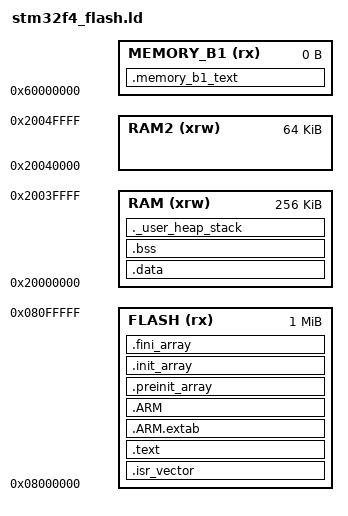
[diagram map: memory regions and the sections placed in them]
/*
*****************************************************************************
**
**  File        : stm32f4_flash.ld
**
**  Abstract    : Linker script for STM32F407VG Device with
**                1024KByte FLASH, 192KByte RAM
**
**                Set heap size, stack size and stack location according
**                to application requirements.
**
**                Set memory bank area and size if external memory is used.
**
**  Target      : STMicroelectronics STM32
**
**  Environment : Atollic TrueSTUDIO(R)
**
**  Distribution: The file is distributed "as is," without any warranty
**                of any kind.
**
**  (c)Copyright Atollic AB.
**  You may use this file as-is or modify it according to the needs of your
**  project. Distribution of this file (unmodified or modified) is not
**  permitted. Atollic AB permit registered Atollic TrueSTUDIO(R) users the
**  rights to distribute the assembled, compiled & linked contents of this
**  file as part of an application binary file, provided that it is built
**  using the Atollic TrueSTUDIO(R) toolchain.
**
*****************************************************************************
*/

/* Entry Point */
ENTRY(Reset_Handler)

/* Highest address of the user mode stack */
enter_bootloader_mode = 0x2001FFFC;
_estack = 0x2001FFFC;    /* end of 128K RAM on AHB bus*/
_app_start = 0x08004000; /* Reserve Sector 0(16K) for bootloader */

/* Generate a link error if heap and stack don't fit into RAM */
_Min_Heap_Size = 0;      /* required amount of heap  */
_Min_Stack_Size = 0x400; /* required amount of stack */

/* Specify the memory areas */
MEMORY
{
  FLASH (rx)      : ORIGIN = 0x08000000, LENGTH = 1024K
  RAM (xrw)       : ORIGIN = 0x20000000, LENGTH = 256K
  RAM2 (xrw)      : ORIGIN = 0x20040000, LENGTH = 64K
  MEMORY_B1 (rx)  : ORIGIN = 0x60000000, LENGTH = 0K
}

/* Define output sections */
SECTIONS
{
  /* The startup code goes first into FLASH */
  .isr_vector :
  {
    . = ALIGN(4);
    KEEP(*(.isr_vector)) /* Startup code */
    . = ALIGN(4);
  } >FLASH

  /* The program code and other data goes into FLASH */
  .text :
  {
    . = ALIGN(4);
    *(.text)           /* .text sections (code) */
    *(.text*)          /* .text* sections (code) */
    *(.rodata)         /* .rodata sections (constants, strings, etc.) */
    *(.rodata*)        /* .rodata* sections (constants, strings, etc.) */
    *(.glue_7)         /* glue arm to thumb code */
    *(.glue_7t)        /* glue thumb to arm code */
	*(.eh_frame)

    KEEP (*(.init))
    KEEP (*(.fini))

    . = ALIGN(4);
    _etext = .;        /* define a global symbols at end of code */
    _exit = .;
  } >FLASH


   .ARM.extab   : { *(.ARM.extab* .gnu.linkonce.armextab.*) } >FLASH
    .ARM : {
    __exidx_start = .;
      *(.ARM.exidx*)
      __exidx_end = .;
    } >FLASH

  .preinit_array     :
  {
    PROVIDE_HIDDEN (__preinit_array_start = .);
    KEEP (*(.preinit_array*))
    PROVIDE_HIDDEN (__preinit_array_end = .);
  } >FLASH
  .init_array :
  {
    PROVIDE_HIDDEN (__init_array_start = .);
    KEEP (*(SORT(.init_array.*)))
    KEEP (*(.init_array*))
    PROVIDE_HIDDEN (__init_array_end = .);
  } >FLASH
  .fini_array :
  {
    PROVIDE_HIDDEN (__fini_array_start = .);
    KEEP (*(.fini_array*))
    KEEP (*(SORT(.fini_array.*)))
    PROVIDE_HIDDEN (__fini_array_end = .);
  } >FLASH

  /* used by the startup to initialize data */
  _sidata = .;

  /* Initialized data sections goes into RAM, load LMA copy after code */
  .data : AT ( _sidata )
  {
    . = ALIGN(4);
    _sdata = .;        /* create a global symbol at data start */
    *(.data)           /* .data sections */
    *(.data*)          /* .data* sections */

    . = ALIGN(4);
    _edata = .;        /* define a global symbol at data end */
  } >RAM

  /* Uninitialized data section */
  . = ALIGN(4);
  .bss :
  {
    /* This is used by the startup in order to initialize the .bss secion */
    _sbss = .;         /* define a global symbol at bss start */
    __bss_start__ = _sbss;
    *(.bss)
    *(.bss*)
    *(COMMON)

    . = ALIGN(4);
    _ebss = .;         /* define a global symbol at bss end */
    __bss_end__ = _ebss;
  } >RAM

  /* User_heap_stack section, used to check that there is enough RAM left */
  ._user_heap_stack :
  {
    . = ALIGN(4);
    PROVIDE ( end = . );
    PROVIDE ( _end = . );
    . = . + _Min_Heap_Size;
    . = . + _Min_Stack_Size;
    . = ALIGN(4);
  } >RAM

  /* MEMORY_bank1 section, code must be located here explicitly            */
  /* Example: extern int foo(void) __attribute__ ((section (".mb1text"))); */
  .memory_b1_text :
  {
    *(.mb1text)        /* .mb1text sections (code) */
    *(.mb1text*)       /* .mb1text* sections (code)  */
    *(.mb1rodata)      /* read-only data (constants) */
    *(.mb1rodata*)
  } >MEMORY_B1

  .ARM.attributes 0 : { *(.ARM.attributes) }
}
